# L4PER_CM_CORE register map
Vendor: Texas Instruments
Peripheral module from a debugger description file (folder TDA3x).
Registers are 32-bit, access per field, reset 0x30000 unless marked. A register's access mark holds for its fields unless they carry their own. Offsets are as the file gives them; lines under a group give offsets from that group; [hi:lo] are bit positions; {n}, {i} and the like mark numbered series; 'fields as' and 'values as' point back to an identical list; <NAME> marks a mode.

## L4PER_CM_CORE
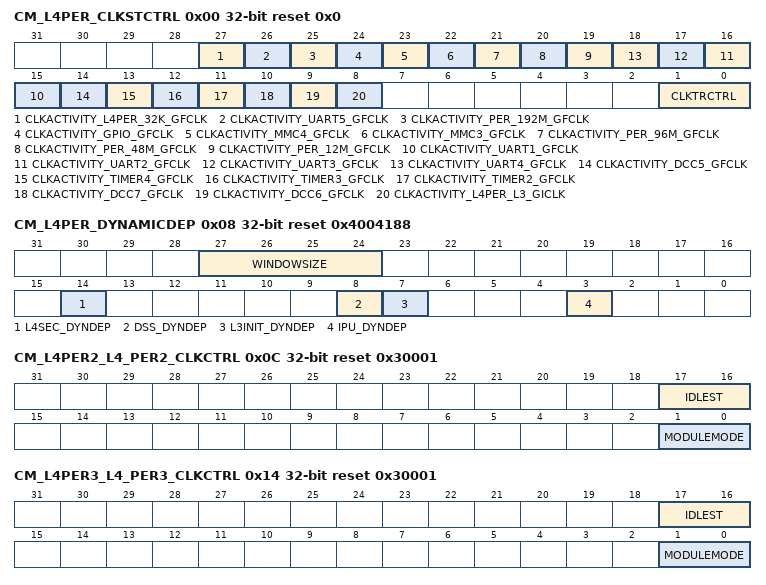
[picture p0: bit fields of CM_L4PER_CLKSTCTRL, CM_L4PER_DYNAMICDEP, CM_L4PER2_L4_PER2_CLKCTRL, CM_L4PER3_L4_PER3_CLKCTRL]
0x00 CM_L4PER_CLKSTCTRL reset 0x0 — This register enables the domain power state transition. It controls the HW supervised domain power state transition between ON-ACTIVE and ON-INACTIVE states. It also hold one status bit per clock input of the domain.
  [27] CLKACTIVITY_L4PER_32K_GFCLK ro — This field indicates the state of the L4PER_32K_FCLK clock in the domain. [warm reset insensitive]
    0=INACT (Corresponding clock is definitely gated); 1=ACT (Corresponding clock is running or gating/ungating transition is on-going)
  [26] CLKACTIVITY_UART5_GFCLK ro — This field indicates the state of the UART5_GFCLK clock in the domain. [warm reset insensitive]
    values as CLKACTIVITY_L4PER_32K_GFCLK
  [25] CLKACTIVITY_PER_192M_GFCLK ro — This field indicates the state of the PER_192M_GFCLK clock in the domain. [warm reset insensitive]
    values as CLKACTIVITY_L4PER_32K_GFCLK
  [24] CLKACTIVITY_GPIO_GFCLK ro — This field indicates the state of the GPIO_GFCLK clock in the domain. [warm reset insensitive]
    values as CLKACTIVITY_L4PER_32K_GFCLK
  [23] CLKACTIVITY_MMC4_GFCLK ro — This field indicates the state of the MMC4_GFCLK clock in the domain. [warm reset insensitive]
    values as CLKACTIVITY_L4PER_32K_GFCLK
  [22] CLKACTIVITY_MMC3_GFCLK ro — This field indicates the state of the MMC3_GFCLK clock in the domain. [warm reset insensitive]
    values as CLKACTIVITY_L4PER_32K_GFCLK
  [21] CLKACTIVITY_PER_96M_GFCLK ro — This field indicates the state of the PER_96M_GFCLK clock in the domain. [warm reset insensitive]
    values as CLKACTIVITY_L4PER_32K_GFCLK
  [20] CLKACTIVITY_PER_48M_GFCLK ro — This field indicates the state of the PER_48M_GFCLK clock in the domain. [warm reset insensitive]
    values as CLKACTIVITY_L4PER_32K_GFCLK
  [19] CLKACTIVITY_PER_12M_GFCLK ro — This field indicates the state of the PER_12M_GFCLK clock in the domain. [warm reset insensitive]
    values as CLKACTIVITY_L4PER_32K_GFCLK
  [n+14] CLKACTIVITY_UART{n}_GFCLK ro (n=1..4) — This field indicates the state of the UART{n}_GFCLK clock in the domain. [warm reset insensitive]
    values as CLKACTIVITY_L4PER_32K_GFCLK
  [14] CLKACTIVITY_DCC5_GFCLK ro — This field indicates the state of the DMT9_GFCLK clock in the domain. [warm reset insensitive]
    values as CLKACTIVITY_L4PER_32K_GFCLK
  [13] CLKACTIVITY_TIMER4_GFCLK ro — This field indicates the state of the DMT4_GFCLK clock in the domain. [warm reset insensitive]
    values as CLKACTIVITY_L4PER_32K_GFCLK
  [12] CLKACTIVITY_TIMER3_GFCLK ro — This field indicates the state of the DMT3_GFCLK clock in the domain. [warm reset insensitive]
    values as CLKACTIVITY_L4PER_32K_GFCLK
  [11] CLKACTIVITY_TIMER2_GFCLK ro — This field indicates the state of the DMT2_GFCLK clock in the domain. [warm reset insensitive]
    values as CLKACTIVITY_L4PER_32K_GFCLK
  [10] CLKACTIVITY_DCC7_GFCLK ro — This field indicates the state of the DMT11_GFCLK clock in the domain. [warm reset insensitive]
    values as CLKACTIVITY_L4PER_32K_GFCLK
  [9] CLKACTIVITY_DCC6_GFCLK ro — This field indicates the state of the DMT10_GFCLK clock in the domain. [warm reset insensitive]
    values as CLKACTIVITY_L4PER_32K_GFCLK
  [8] CLKACTIVITY_L4PER_L3_GICLK ro — This field indicates the state of the L4PER_L3_GICLK clock in the domain. [warm reset insensitive]
    values as CLKACTIVITY_L4PER_32K_GFCLK
  [1:0] CLKTRCTRL rw — Controls the clock state transition of the L4PER clock domain.
    0=NO_SLEEP (NO_SLEEP: Sleep transition cannot be initiated. Wakeup transition may however occur.); 1=SW_SLEEP (SW_SLEEP: Start a software forced sleep transition on the domain.); 2=SW_WKUP (SW_WKUP: Start a software forced wake-up transition on the domain.); 3=HW_AUTO (HW_AUTO: Automatic transition is enabled. Sleep and wakeup transition are based upon hardware conditions.)
0x08 CM_L4PER_DYNAMICDEP reset 0x4004188 — This register controls the dynamic domain depedencies from L4PER domain towards 'target' domains. It is relevant only for domain having OCP master port(s).
  [27:24] WINDOWSIZE rw — Size of sliding window used to monitor OCP interface activity for determination of auto-sleep feature. Time unit defined byCM_DYN_DEP_PRESCAL register.
  [14] L4SEC_DYNDEP ro — Dynamic dependency towards L4SEC clock domain
    1=ENABLED (Dependency is enabled)
  [8] DSS_DYNDEP ro — Dynamic dependency towards DSS clock domain
    1=ENABLED (Dependency is enabled)
  [7] L3INIT_DYNDEP ro — Dynamic dependency towards L3INIT clock domain
    1=ENABLED (Dependency is enabled)
  [3] IPU_DYNDEP ro — Dynamic dependency towards IPU clock domain
    1=ENABLED (Dependency is enabled)
0x0C CM_L4PER2_L4_PER2_CLKCTRL ro reset 0x30001 — This register manages the L4_PER2 clocks.
  [17:16] IDLEST — Module idle status. [warm reset insensitive]
    0=FUNC (Module is fully functional, including OCP); 1=TRANS (Module is performing transition: wakeup, or sleep, or sleep abortion); 2=IDLE (Module is in Idle mode (only OCP part). It is functional if using separate functional clock); 3=DISABLE (Module is disabled and cannot be accessed)
  [1:0] MODULEMODE — Control the way mandatory clocks are managed.
    1=AUTO (Module is managed automatically by HW according to clock domain transition. A clock domain sleep transition put module into idle. A wakeup domain transition put it back into function. If CLKTRCTRL=3, any OCP access to module is always granted. Module clocks may be gated according to the clock domain state.)
0x14 CM_L4PER3_L4_PER3_CLKCTRL ro reset 0x30001 — This register manages the L4_PER3 clocks.
  fields as CM_L4PER2_L4_PER2_CLKCTRL
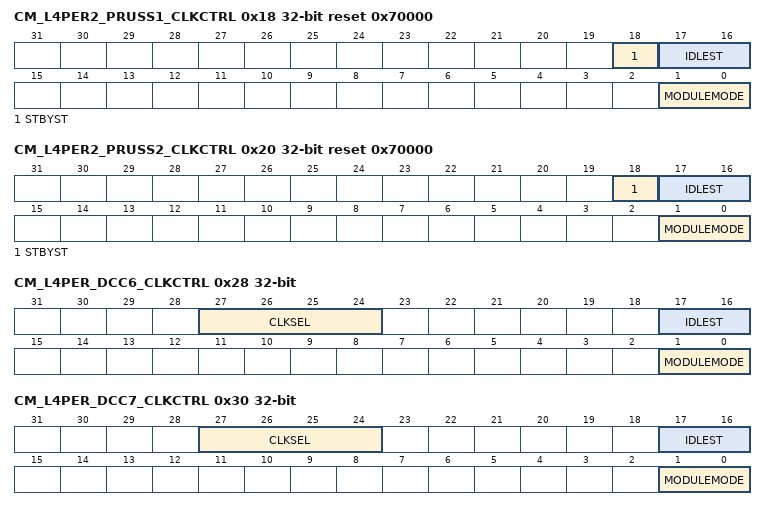
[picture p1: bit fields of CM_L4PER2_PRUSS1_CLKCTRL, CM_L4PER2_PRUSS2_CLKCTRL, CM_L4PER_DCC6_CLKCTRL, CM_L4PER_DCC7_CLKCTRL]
0x18 CM_L4PER2_PRUSS1_CLKCTRL reset 0x70000 — This register manages the PRUSS clocks.
  [18] STBYST ro — Module standby status. [warm reset insensitive]
    0=FUNC (Module is functional (not in standby)); 1=STANDBY (Module is in standby)
  [17:16] IDLEST ro — Module idle status. [warm reset insensitive]
    values as CM_L4PER2_L4_PER2_CLKCTRL.IDLEST
  [1:0] MODULEMODE rw — Control the way mandatory clocks are managed.
    0=DISABLED (Module is disabled by SW. Any OCP access to module results in an error, except if resulting from a module wakeup (asynchronous wakeup).); 2=ENABLE (Module is explicitly enabled. Interface clock (if not used for functions) may be gated according to the clock domain state. Functional clocks are guaranteed to stay present. As long as in this configuration, power domain sleep transition cannot happen.)
0x20 CM_L4PER2_PRUSS2_CLKCTRL reset 0x70000 — This register manages the PRUSS clocks.
  fields as CM_L4PER2_PRUSS1_CLKCTRL
0x28 CM_L4PER_DCC6_CLKCTRL — This register manages the DCC6 clocks.
  [27:24] CLKSEL rw — Select the source of the functional clock
    0=SEL_TIMER_SYS_CLK (Selects the TIMER_SYS_CLK as the source); 1=SEL_SYS_CLK1_32K_CLK (Selects the SYS_CLK1_32K_CLK as the source); 2=SEL_SYS_CLK2 (Selects SYS_CLK2); {v}=SEL_XREF_CLK{v-3} (Selects XREF_CLK{v-3}) (v=3..6); 7=SEL_ABE_GICLK (Selects ABE_GICLK); 8=SEL_VIDEO1_CLK (Selects VIDEO1 CLK); 9=SEL_VIDEO2_CLK (Selects VIDEO2 CLK); 10=SEL_HDMI_CLK (Selects HDMI CLK)
  [17:16] IDLEST ro — Module idle status. [warm reset insensitive]
    values as CM_L4PER2_L4_PER2_CLKCTRL.IDLEST
  [1:0] MODULEMODE rw — Control the way mandatory clocks are managed.
    values as CM_L4PER2_PRUSS1_CLKCTRL.MODULEMODE
0x30 CM_L4PER_DCC7_CLKCTRL — This register manages the DCC7 clocks.
  fields as CM_L4PER_DCC6_CLKCTRL
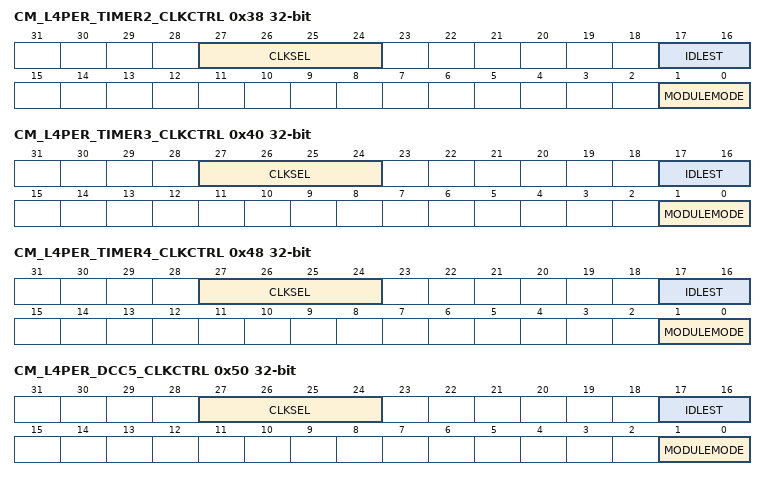
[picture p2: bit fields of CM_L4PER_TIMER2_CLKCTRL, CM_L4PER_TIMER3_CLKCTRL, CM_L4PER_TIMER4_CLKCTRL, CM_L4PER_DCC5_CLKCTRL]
0x38 CM_L4PER_TIMER2_CLKCTRL — This register manages the TIMER2 clocks.
  [27:24] CLKSEL rw — Select the source of the functional clockOthers: RESERVED .
    0=SEL_TIMER_SYS_CLK (Selects SYS_CLK1); 1=SEL_FUNC_32K_CLK (Selects FUNC_32K_CLK); 2=SEL_SYS_CLK2 (Selects SYS_CLK2); 3=SEL_XREF_CLK0 (Selects XREF_CLK0); 4=SEL_XREF_CLK1 (Selects XREF_CLK1); 5=SEL_XREF_CLK2 (Selects XREF_CLK0); 6=SEL_XREF_CLK3 (Selects XREF_CLK1); 7=SEL_ABE_GICLK (Selects ABE_GICLK); 8=SEL_VIDEO1_CLK (Selects divided version of SYS_CLK1. See); 9=SEL_VIDEO2_CLK (Selects divided version of SYS_CLK1. See); 10=SEL_HDMI_CLK (Selects divided version of SYS_CLK1. See)
  [17:16] IDLEST ro — Module idle status. [warm reset insensitive]
    values as CM_L4PER2_L4_PER2_CLKCTRL.IDLEST
  [1:0] MODULEMODE rw — Control the way mandatory clocks are managed.
    values as CM_L4PER2_PRUSS1_CLKCTRL.MODULEMODE
0x40 CM_L4PER_TIMER3_CLKCTRL — This register manages the TIMER3 clocks.
  [27:24] CLKSEL rw — Select the source of the functional clockOthers: RESERVED enum=RESERVED4 .
    0=SEL_TIMER_SYS_CLK (Selects SYS_CLK1); 1=SEL_FUNC_32K_CLK (Selects FUNC_32K_CLK); 2=SEL_SYS_CLK2 (Selects SYS_CLK2); 3=SEL_XREF_CLK0 (Selects XREF_CLK0); 4=SEL_XREF_CLK1 (Selects XREF_CLK1); 5=SEL_XREF_CLK2 (Selects XREF_CLK0); 6=SEL_XREF_CLK3 (Selects XREF_CLK1); 7=SEL_PER_ABE_X1_GFCLK (Selects ABE_GICLK); 8=SEL_VIDEO1_CLK (Selects divided version of SYS_CLK1. See); 9=SEL_VIDEO2_CLK (Selects divided version of SYS_CLK1. See); 10=SEL_HDMI_CLK (Selects divided version of SYS_CLK1. See)
  [17:16] IDLEST ro — Module idle status. [warm reset insensitive]
    values as CM_L4PER2_L4_PER2_CLKCTRL.IDLEST
  [1:0] MODULEMODE rw — Control the way mandatory clocks are managed.
    values as CM_L4PER2_PRUSS1_CLKCTRL.MODULEMODE
0x48 CM_L4PER_TIMER4_CLKCTRL — This register manages the TIMER4 clocks.
  [27:24] CLKSEL rw — Select the source of the functional clockOthers: RESERVED .
    values as CM_L4PER_TIMER3_CLKCTRL.CLKSEL
  [17:16] IDLEST ro — Module idle status. [warm reset insensitive]
    values as CM_L4PER2_L4_PER2_CLKCTRL.IDLEST
  [1:0] MODULEMODE rw — Control the way mandatory clocks are managed.
    values as CM_L4PER2_PRUSS1_CLKCTRL.MODULEMODE
0x50 CM_L4PER_DCC5_CLKCTRL — This register manages the DCC5 clocks.
  [27:24] CLKSEL rw — Select the source of the functional clock
    0=SEL_TIMER_SYS_CLK (Selects the TIMER_SYS_CLK as the source); 1=SEL_SYS_CLK1_32K_CLK (Selects the SYS_CLK1_32K_CLK as the source); 2=SEL_SYS_CLK2 (Selects SYS_CLK2); {v}=SEL_XREF_CLK{v-3} (Selects XREF_CLK{v-3}) (v=3..6); 7=SEL_PER_ABE_X1_GFCLK (Selects PER_ABE_X1 CLK); 8=SEL_VIDEO1_CLK (Selects VIDEO1 CLK); 9=SEL_VIDEO2_CLK (Selects VIDEO2 CLK); 10=SEL_HDMI_CLK (Selects HDMI CLK)
  [17:16] IDLEST ro — Module idle status. [warm reset insensitive]
    values as CM_L4PER2_L4_PER2_CLKCTRL.IDLEST
  [1:0] MODULEMODE rw — Control the way mandatory clocks are managed.
    values as CM_L4PER2_PRUSS1_CLKCTRL.MODULEMODE
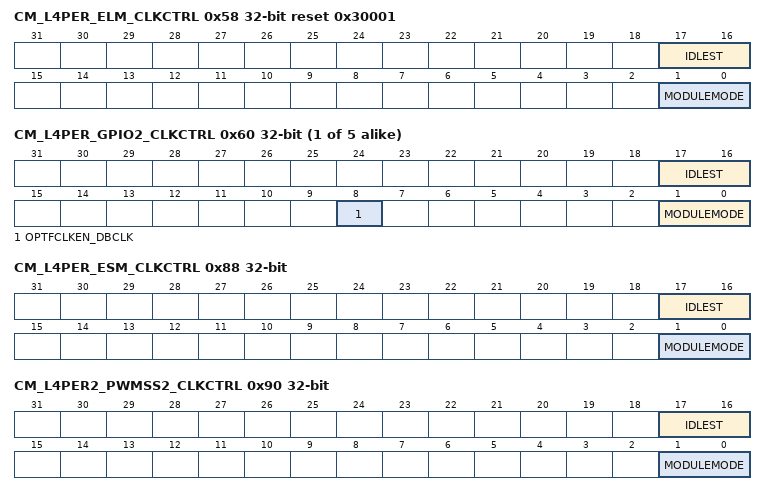
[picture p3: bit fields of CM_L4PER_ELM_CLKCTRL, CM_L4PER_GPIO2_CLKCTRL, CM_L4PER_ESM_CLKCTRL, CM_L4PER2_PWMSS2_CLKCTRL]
0x58 CM_L4PER_ELM_CLKCTRL ro reset 0x30001 — This register manages the ELM clocks.
  fields as CM_L4PER2_L4_PER2_CLKCTRL
{0x50+8i} CM_L4PER_GPIO{i}_CLKCTRL (i=2..6) — This register manages the GPIO{i} clocks.
  [17:16] IDLEST ro — Module idle status. [warm reset insensitive]
    values as CM_L4PER2_L4_PER2_CLKCTRL.IDLEST
  [8] OPTFCLKEN_DBCLK rw — Optional functional clock control.
    0=FCLK_DIS (Optional functional clock is disabled); 1=FCLK_EN (Optional functional clock is enabled)
  [1:0] MODULEMODE rw — Control the way mandatory clocks are managed.
    0=DISABLED (Module is disabled by SW. Any OCP access to module results in an error, except if resulting from a module wakeup (asynchronous wakeup).); 1=AUTO (Module is managed automatically by HW according to clock domain transition. A clock domain sleep transition put module into idle. A wakeup domain transition put it back into function. If CLKTRCTRL=3, any OCP access to module is always granted. Module clocks may be gated according to the clock domain state.)
0x88 CM_L4PER_ESM_CLKCTRL — This register manages the ESM clocks.
  [17:16] IDLEST ro — Module idle status. [warm reset insensitive]
    values as CM_L4PER2_L4_PER2_CLKCTRL.IDLEST
  [1:0] MODULEMODE rw — Control the way mandatory clocks are managed.
    values as CM_L4PER2_PRUSS1_CLKCTRL.MODULEMODE
0x90 CM_L4PER2_PWMSS2_CLKCTRL — This register manages the PWMSS1 clocks.
  fields as CM_L4PER_ESM_CLKCTRL
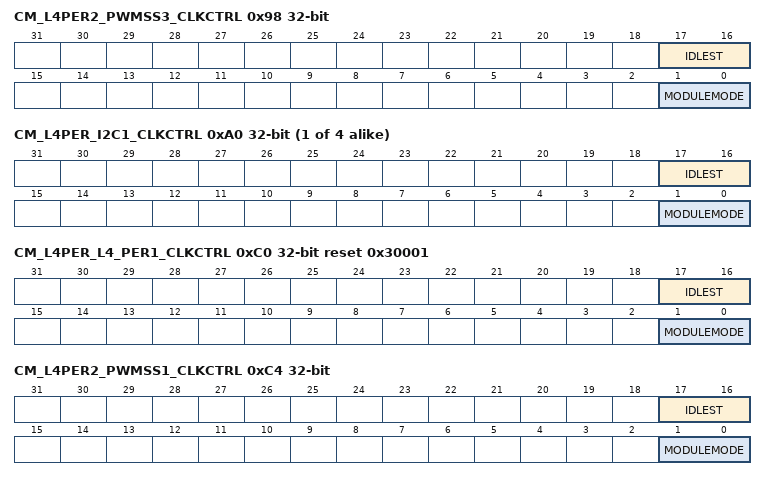
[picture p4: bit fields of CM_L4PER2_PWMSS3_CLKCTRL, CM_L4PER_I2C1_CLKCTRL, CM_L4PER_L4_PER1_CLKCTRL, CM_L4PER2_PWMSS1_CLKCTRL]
0x98 CM_L4PER2_PWMSS3_CLKCTRL — This register manages the PWMSS2 clocks.
  fields as CM_L4PER_ESM_CLKCTRL
{0x98+8i} CM_L4PER_I2C{i}_CLKCTRL (i=1..4) — This register manages the I2C{i} clocks.
  fields as CM_L4PER_ESM_CLKCTRL
0xC0 CM_L4PER_L4_PER1_CLKCTRL ro reset 0x30001 — This register manages the L4_PER1 clocks.
  fields as CM_L4PER2_L4_PER2_CLKCTRL
0xC4 CM_L4PER2_PWMSS1_CLKCTRL — This register manages the PWMSS1 clocks.
  fields as CM_L4PER_ESM_CLKCTRL
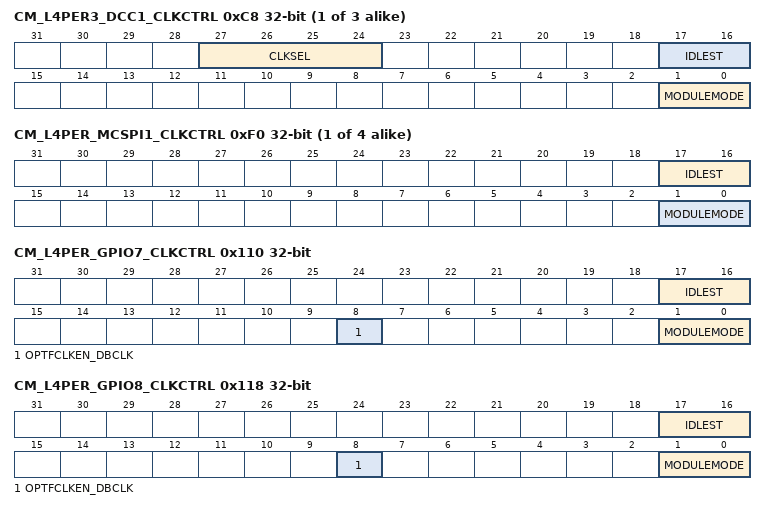
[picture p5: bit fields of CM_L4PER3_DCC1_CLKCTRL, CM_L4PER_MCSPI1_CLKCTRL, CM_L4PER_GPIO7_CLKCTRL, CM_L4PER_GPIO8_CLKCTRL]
{0xC0+8i} CM_L4PER3_DCC{i}_CLKCTRL (i=1..3) — This register manages the DCC{i} clocks.
  fields as CM_L4PER_DCC5_CLKCTRL
{0xE8+8i} CM_L4PER_MCSPI{i}_CLKCTRL (i=1..4) — This register manages the MCSPI{i} clocks.
  fields as CM_L4PER_ESM_CLKCTRL
0x110 CM_L4PER_GPIO7_CLKCTRL — This register manages the GPIO7 clocks.
  fields as CM_L4PER_GPIO2_CLKCTRL
0x118 CM_L4PER_GPIO8_CLKCTRL — This register manages the GPIO8 clocks.
  fields as CM_L4PER_GPIO2_CLKCTRL
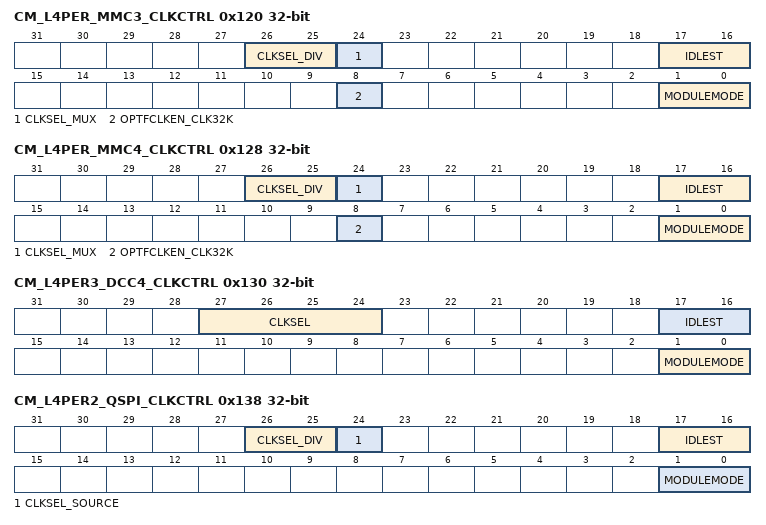
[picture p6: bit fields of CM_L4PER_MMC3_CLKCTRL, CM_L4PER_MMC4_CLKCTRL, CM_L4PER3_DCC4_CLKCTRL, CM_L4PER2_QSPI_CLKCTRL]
0x120 CM_L4PER_MMC3_CLKCTRL — This register manages the MMC3 clocks.
  [26:25] CLKSEL_DIV rw — Selects the divider value
    0=MMCCLK_DIV_1 (Select MMC CLK divided by 1); 1=MMCCLK_DIV_2 (Select MMC CLK divided by 2); 2=MMCCLK_DIV_4 (Selects MMC CLK divided by 4)
  [24] CLKSEL_MUX rw — Select the clock for the MMC from DPLL_PER.
    0=SEL_FUNC_48M_CLK (Selects FUNC_48M_CLK); 1=SEL_FUNC_192M_CLK (Selects FUNC_192M_CLK)
  [17:16] IDLEST ro — Module idle status. [warm reset insensitive]
    values as CM_L4PER2_L4_PER2_CLKCTRL.IDLEST
  [8] OPTFCLKEN_CLK32K rw — MMC optional clock control: 32K CLK
    values as CM_L4PER_GPIO2_CLKCTRL.OPTFCLKEN_DBCLK
  [1:0] MODULEMODE rw — Control the way mandatory clocks are managed.
    values as CM_L4PER2_PRUSS1_CLKCTRL.MODULEMODE
0x128 CM_L4PER_MMC4_CLKCTRL — This register manages the MMC4 clocks.
  [26:25] CLKSEL_DIV rw — Selects the divider value
    0=MMCCLK_DIV_1 (Selects MMC CLK divided by 1); 1=MMCCLK_DIV_2 (Selects MMC CLK divided by 2); 2=MMCCLK_DIV_4 (Selects MMC CLK divided by 4)
  [24] CLKSEL_MUX rw — Select the clock for the MMC from DPLL_PER.
    values as CM_L4PER_MMC3_CLKCTRL.CLKSEL_MUX
  [17:16] IDLEST ro — Module idle status. [warm reset insensitive]
    values as CM_L4PER2_L4_PER2_CLKCTRL.IDLEST
  [8] OPTFCLKEN_CLK32K rw — MMC optional clock control: 32K CLK
    values as CM_L4PER_GPIO2_CLKCTRL.OPTFCLKEN_DBCLK
  [1:0] MODULEMODE rw — Control the way mandatory clocks are managed.
    values as CM_L4PER2_PRUSS1_CLKCTRL.MODULEMODE
0x130 CM_L4PER3_DCC4_CLKCTRL — This register manages the DCC4 clocks.
  fields as CM_L4PER_DCC5_CLKCTRL
0x138 CM_L4PER2_QSPI_CLKCTRL — This register manages the QSPI clocks.
  [26:25] CLKSEL_DIV rw — QSPI clock divide ratio.
    0=DIV1 (QSPI clock is divided by 1.); 1=DIV2 (QSPI clock is divided by 2.); 2=DIV4 (QSPI clock is divided by 4.)
  [24] CLKSEL_SOURCE rw — Selects the source of the functional clock.
    0=SEL_FUNC_128M_CLK (FUNC_128M_CLK from DPLL_PER is selected); 1=SEL_PER_QSPI_CLK (Selects PER_QSPI_CLK from DPLL_PER)
  [17:16] IDLEST ro — Module idle status. [warm reset insensitive]
    values as CM_L4PER2_L4_PER2_CLKCTRL.IDLEST
  [1:0] MODULEMODE rw — Control the way mandatory clocks are managed.
    0=DISABLED (Module is disabled by SW. Any OCP access to module results in an error, except if resulting from a module wakeup (asynchronous wakeup).); 2=ENABLED (Module is explicitly enabled. Interface clock (if not used for functions) may be gated according to the clock domain state. Functional clocks are guaranteed to stay present. As long as in this configuration, power domain sleep transition cannot happen.)
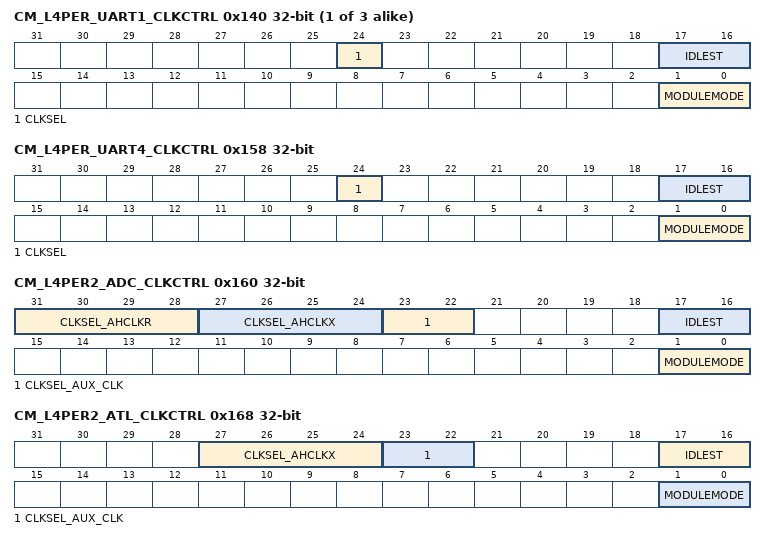
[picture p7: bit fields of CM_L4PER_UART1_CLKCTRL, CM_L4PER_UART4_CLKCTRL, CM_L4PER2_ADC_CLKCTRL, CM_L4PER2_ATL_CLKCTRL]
{0x138+8i} CM_L4PER_UART{i}_CLKCTRL (i=1..3) — This register manages the UART{i} clocks.
  [24] CLKSEL rw — Selects functional clock for UART between FUNC_48M_CLK and FUNC_192M_CLK
    values as CM_L4PER_MMC3_CLKCTRL.CLKSEL_MUX
  [17:16] IDLEST ro — Module idle status. [warm reset insensitive]
    values as CM_L4PER2_L4_PER2_CLKCTRL.IDLEST
  [1:0] MODULEMODE rw — Control the way mandatory clocks are managed.
    values as CM_L4PER2_PRUSS1_CLKCTRL.MODULEMODE
0x158 CM_L4PER_UART4_CLKCTRL — This register manages the UART4 clocks.
  [24] CLKSEL rw — Selects functional clock for UART between FUNCTION_48M_CLK and FUNC_192M_CLK
    values as CM_L4PER_MMC3_CLKCTRL.CLKSEL_MUX
  [17:16] IDLEST ro — Module idle status. [warm reset insensitive]
    values as CM_L4PER2_L4_PER2_CLKCTRL.IDLEST
  [1:0] MODULEMODE rw — Control the way mandatory clocks are managed.
    values as CM_L4PER2_PRUSS1_CLKCTRL.MODULEMODE
0x160 CM_L4PER2_ADC_CLKCTRL — This register manages the ADC clocks. In TDA2x, this register is CM_L4PER2_MCASP2_CLKCTRL
  [31:28] CLKSEL_AHCLKR rw — Selects reference clock for AHCLKR
    0=SEL_ABE_24M_GFCLK (Selects ABE_24M_GFCLK); 1=SEL_ABE_SYS_CLK (Selects ABE_SYS_CLK); 2=SEL_FUNC_24M_GFCLK (Selects FUNC_24M_GFCLK); 3=SEL_CRC_CLK3 (Selects ATL CLK3); 4=SEL_CRC_CLK2 (Selects ATL CLK2); 5=SEL_CRC_CLK1 (Selects ATL CLK1); 6=SEL_CRC_CLK0 (Selects ATL CLK0); 7=SEL_SYS_SLK2 (Selects SYS_CLK2); {v}=SEL_XREF_CLK{v-8} (Selects XREF_CLK{v-8}) (v=8..11); 12=SEL_MLB_CLK (Selects MLB_CLK); 13=SEL_MLBP_CLK (Selects MLBP_CLK)
  [27:24] CLKSEL_AHCLKX rw — Selects reference clock for AHCLKX
    values as CLKSEL_AHCLKR
  [23:22] CLKSEL_AUX_CLK rw — Selects the source of the AUX clock
    0=SEL_PER_ABE_X1_GFCLK (Selects PER_ABE_X1_GFCLK); 1=SEL_VIDEO1_CLK (Selects VIDEO1 CLK); 2=SEL_VIDEO2_CLK (Selects VIDEO2 CLK); 3=SEL_HDMI_CLK (Selects HDMI CLK)
  [17:16] IDLEST ro — Module idle status. [warm reset insensitive]
    values as CM_L4PER2_L4_PER2_CLKCTRL.IDLEST
  [1:0] MODULEMODE rw — Control the way mandatory clocks are managed.
    values as CM_L4PER2_PRUSS1_CLKCTRL.MODULEMODE
0x168 CM_L4PER2_ATL_CLKCTRL — This register manages the ATL module mode (SR2.0). In TDA2x, this register is CM_L4PER2_MCASP3_CLKCTRL
  [27:24] CLKSEL_AHCLKX rw — Selects reference clock for AHCLKX
    values as CM_L4PER2_ADC_CLKCTRL.CLKSEL_AHCLKR
  [23:22] CLKSEL_AUX_CLK rw — Selects the source of the AUX clock
    values as CM_L4PER2_ADC_CLKCTRL.CLKSEL_AUX_CLK
  [17:16] IDLEST ro — Module idle status. [warm reset insensitive]
    values as CM_L4PER2_L4_PER2_CLKCTRL.IDLEST
  [1:0] MODULEMODE rw — Control the way mandatory clocks are managed.
    values as CM_L4PER2_PRUSS1_CLKCTRL.MODULEMODE
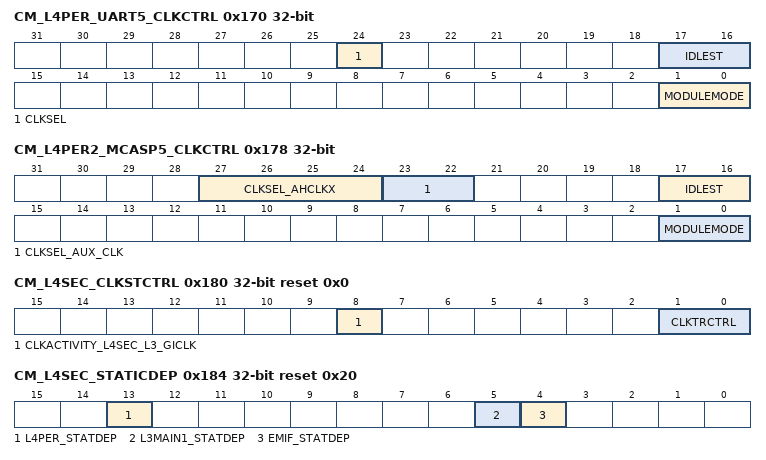
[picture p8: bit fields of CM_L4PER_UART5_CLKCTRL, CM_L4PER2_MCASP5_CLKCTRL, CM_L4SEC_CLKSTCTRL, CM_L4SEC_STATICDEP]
0x170 CM_L4PER_UART5_CLKCTRL — This register manages the UART5 clocks.
  fields as CM_L4PER_UART4_CLKCTRL
0x178 CM_L4PER2_MCASP5_CLKCTRL — This register manages the MCASP3 clocks (SR2.0).
  [27:24] CLKSEL_AHCLKX rw — Selects reference clock for AHCLKX
    0=SEL_ABE_24M_GFCLK (Selects ABE_24M_GFCLK); 1=SEL_ABE_SYS_CLK (Selects ABE_SYS_CLK); 2=SEL_FUNC_24M_GFCLK (Selects FUNC_24M_GFCLK); 3=SEL_ATL_CLK3 (Selects ATL_CLK3); 4=SEL_ATL_CLK2 (Selects ATL_CLK2); 5=SEL_ATL_CLK1 (Selects ATL_CLK1); 6=SEL_ATL_CLK0 (Selects ATL_CLK0); 7=SEL_SYS_SLK2 (Selects SYS_CLK2); 8=SEL_XREF_CLK0 (Selects XREF_CLK0); 9=SEL_XREF_CLK1 (Selects XREF_CLK1); 10=SEL_XREF_CLK2 (Selects XREF_CLK2); 11=SEL_XREF_CLK3 (Selects XREF_CLK1); 12=SEL_MLB_CLK (Selects divided version of SYS_CLK1. See); 13=SEL_MLBP_CLK (Selects divided version of SYS_CLK1. See)
  [23:22] CLKSEL_AUX_CLK rw — Selects the source of the AUX clock.
    0=SEL_PER_ABE_X1_GFCLK (Selects divided version of L4_ICLK. See); 1=SEL_VIDEO1_CLK (Selects divided version of SYS_CLK1. See); 2=SEL_VIDEO2_CLK (Selects divided version of SYS_CLK1. See); 3=SEL_HDMI_CLK (Selects divided version of SYS_CLK1. See)
  [17:16] IDLEST ro — Module idle status. [warm reset insensitive]
    values as CM_L4PER2_L4_PER2_CLKCTRL.IDLEST
  [1:0] MODULEMODE rw — Control the way mandatory clocks are managed.
    values as CM_L4PER2_PRUSS1_CLKCTRL.MODULEMODE
0x180 CM_L4SEC_CLKSTCTRL reset 0x0 — This register enables the domain power state transition. It controls the HW supervised domain power state transition between ON-ACTIVE and ON-INACTIVE states. It also hold one status bit per clock input of the domain.
  [8] CLKACTIVITY_L4SEC_L3_GICLK ro — This field indicates the state of the L3_SECURE_GICLK clock in the domain. [warm reset insensitive]
    values as CM_L4PER_CLKSTCTRL.CLKACTIVITY_L4PER_32K_GFCLK
  [1:0] CLKTRCTRL rw — Controls the clock state transition of the L4PER clock domain.
    values as CM_L4PER_CLKSTCTRL.CLKTRCTRL
0x184 CM_L4SEC_STATICDEP reset 0x20 — This register controls the static domain depedencies from L4SEC domain towards 'target' domains. It is relevant only for domain having system initiator(s).
  [13] L4PER_STATDEP rw — Static dependency towards L4PER1 clock domain
    0=DISABLED (Dependency is disabled); 1=ENABLED (Dependency is enabled)
  [5] L3MAIN1_STATDEP ro — Static dependency towards L3MAIN1 clock domain
    1=ENABLED (Dependency is enabled)
  [4] EMIF_STATDEP rw — Static dependency towards EMIF clock domain
    values as L4PER_STATDEP
0x188 CM_L4SEC_DYNAMICDEP ro reset 0x0 — This register controls the dynamic domain depedencies from L4SEC domain towards 'target' domains. It is relevant only for domain having OCP master port(s).
  [5] L3MAIN1_DYNDEP — Dynamic dependency towards L3MAIN1 clock domain
    0=DISABLED (Dependency is disabled)
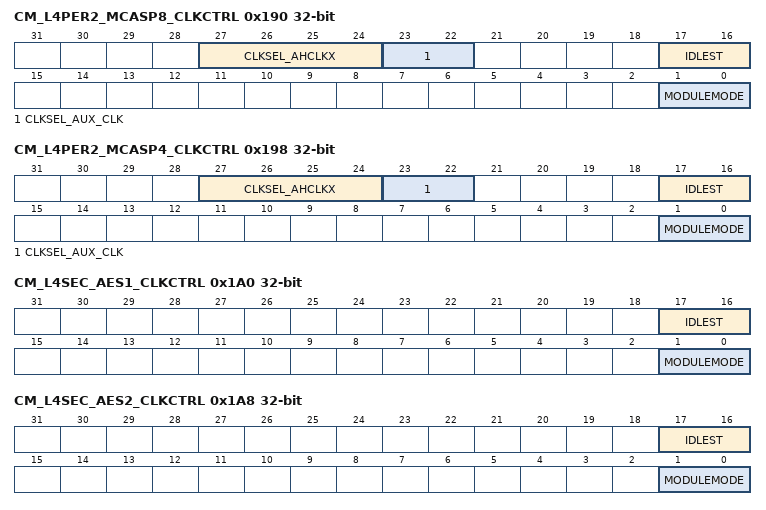
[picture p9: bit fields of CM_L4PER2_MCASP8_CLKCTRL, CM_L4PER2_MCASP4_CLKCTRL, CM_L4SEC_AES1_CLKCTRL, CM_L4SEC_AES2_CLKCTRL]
0x190 CM_L4PER2_MCASP8_CLKCTRL — This register manages the MCASP8 clocks.
  [27:24] CLKSEL_AHCLKX rw — Selects reference clock for AHCLKX
    0=SEL_ABE_24M_GFCLK (Selects ABE_24M_GFCLK); 1=SEL_ABE_SYS_CLK (Selects ABE_SYS_CLK); 2=SEL_FUNC_24M_GFCLK (Selects FUNC_24M_GFCLK); 3=SEL_CRC_CLK3 (Selects CRC CLK3); 4=SEL_CRC_CLK2 (Selects CRC CLK2); 5=SEL_CRC_CLK1 (Selects CRC CLK1); 6=SEL_CRC_CLK0 (Selects CRC CLK0); 7=SEL_SYS_SLK2 (Selects SYS_CLK2); {v}=SEL_XREF_CLK{v-8} (Selects XREF_CLK{v-8}) (v=8..11); 12=SEL_MLB_CLK (Selects MLB_CLK); 13=SEL_MLBP_CLK (Selects MLBP_CLK)
  [23:22] CLKSEL_AUX_CLK rw — Selects the source of the AUX clock
    values as CM_L4PER2_ADC_CLKCTRL.CLKSEL_AUX_CLK
  [17:16] IDLEST ro — Module idle status. [warm reset insensitive]
    values as CM_L4PER2_L4_PER2_CLKCTRL.IDLEST
  [1:0] MODULEMODE rw — Control the way mandatory clocks are managed.
    values as CM_L4PER2_PRUSS1_CLKCTRL.MODULEMODE
0x198 CM_L4PER2_MCASP4_CLKCTRL — This register manages the MCASP2 clocks (SR2.0).
  fields as CM_L4PER2_MCASP5_CLKCTRL
0x1A0 CM_L4SEC_AES1_CLKCTRL — This register manages the AES1 clocks.
  [17:16] IDLEST ro — Module idle status. [warm reset insensitive]
    values as CM_L4PER2_L4_PER2_CLKCTRL.IDLEST
  [1:0] MODULEMODE rw — Control the way mandatory clocks are managed.
    values as CM_L4PER_GPIO2_CLKCTRL.MODULEMODE
0x1A8 CM_L4SEC_AES2_CLKCTRL — This register manages the AES2 clocks.
  fields as CM_L4SEC_AES1_CLKCTRL
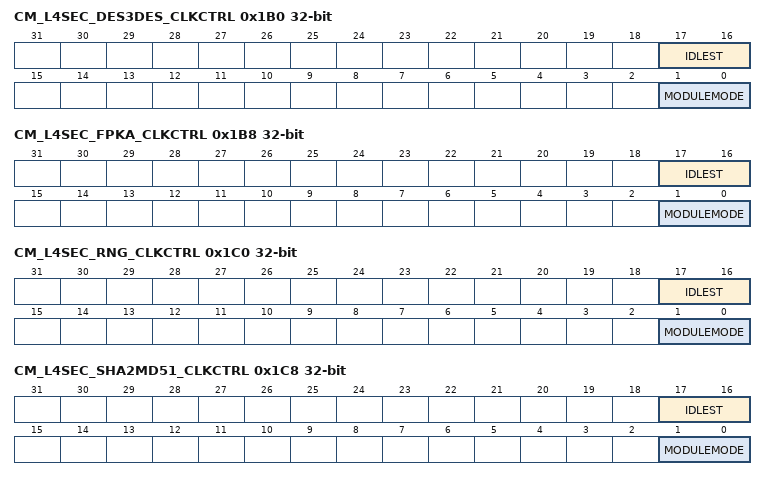
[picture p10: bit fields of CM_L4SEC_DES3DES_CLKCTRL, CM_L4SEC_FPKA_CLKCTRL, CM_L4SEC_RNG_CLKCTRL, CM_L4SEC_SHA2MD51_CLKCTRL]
0x1B0 CM_L4SEC_DES3DES_CLKCTRL — This register manages the DES3DES clocks.
  fields as CM_L4SEC_AES1_CLKCTRL
0x1B8 CM_L4SEC_FPKA_CLKCTRL — This register manages the FPKA clocks.
  fields as CM_L4PER_ESM_CLKCTRL
0x1C0 CM_L4SEC_RNG_CLKCTRL — This register manages the RNG clocks.
  fields as CM_L4SEC_AES1_CLKCTRL
0x1C8 CM_L4SEC_SHA2MD51_CLKCTRL — This register manages the SHA2MD51 clocks.
  fields as CM_L4SEC_AES1_CLKCTRL
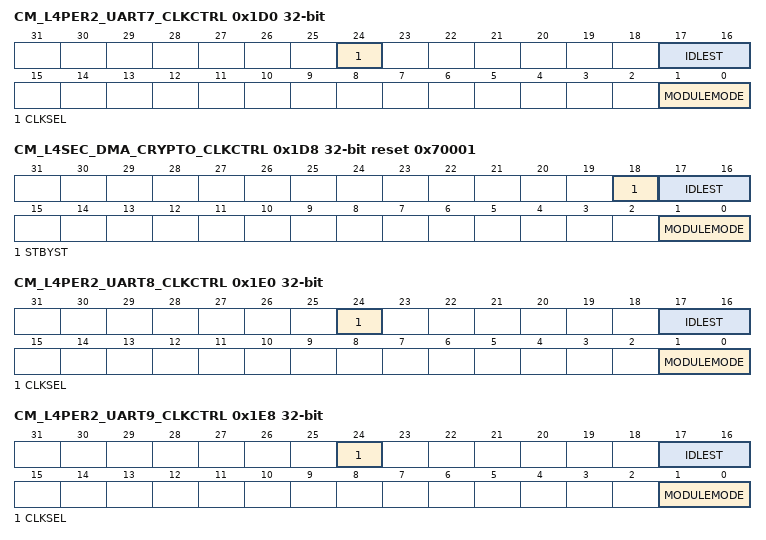
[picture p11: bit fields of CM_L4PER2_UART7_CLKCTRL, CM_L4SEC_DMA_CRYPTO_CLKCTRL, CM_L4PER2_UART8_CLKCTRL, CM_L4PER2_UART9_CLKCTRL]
0x1D0 CM_L4PER2_UART7_CLKCTRL — This register manages the UART7 clocks.
  fields as CM_L4PER_UART4_CLKCTRL
0x1D8 CM_L4SEC_DMA_CRYPTO_CLKCTRL ro reset 0x70001 — This register manages the DMA_CRYPTO clocks.
  [18] STBYST — Module standby status. [warm reset insensitive]
    values as CM_L4PER2_PRUSS1_CLKCTRL.STBYST
  [17:16] IDLEST — Module idle status. [warm reset insensitive]
    values as CM_L4PER2_L4_PER2_CLKCTRL.IDLEST
  [1:0] MODULEMODE — Control the way mandatory clocks are managed.
    values as CM_L4PER2_L4_PER2_CLKCTRL.MODULEMODE
0x1E0 CM_L4PER2_UART8_CLKCTRL — This register manages the UART8 clocks.
  fields as CM_L4PER_UART4_CLKCTRL
0x1E8 CM_L4PER2_UART9_CLKCTRL — This register manages the UART9 clocks.
  fields as CM_L4PER_UART4_CLKCTRL
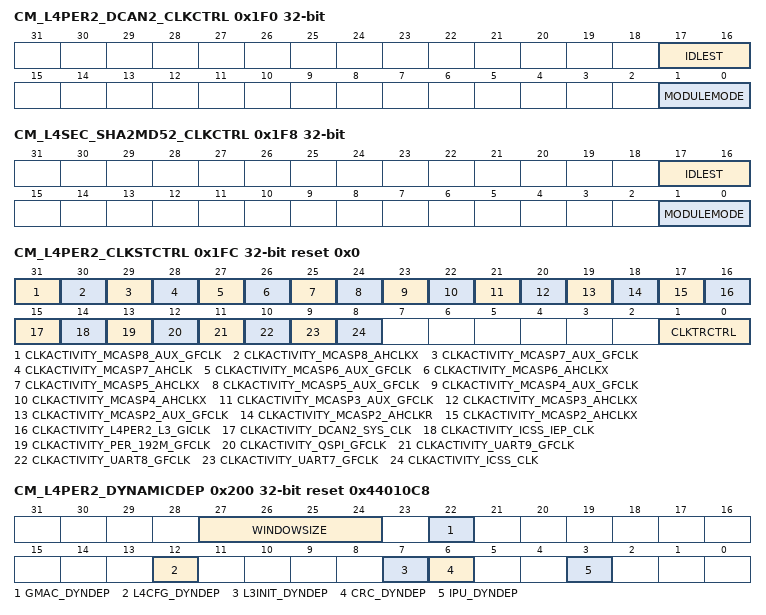
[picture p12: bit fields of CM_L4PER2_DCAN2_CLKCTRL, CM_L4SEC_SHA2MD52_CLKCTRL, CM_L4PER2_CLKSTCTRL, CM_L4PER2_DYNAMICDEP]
0x1F0 CM_L4PER2_DCAN2_CLKCTRL — This register manages the MCAN clocks (SR2.0) or DCAN2 clocks (SR1.0).
  fields as CM_L4PER_ESM_CLKCTRL
0x1F8 CM_L4SEC_SHA2MD52_CLKCTRL — This register manages the SHA2MD52 clocks.
  fields as CM_L4SEC_AES1_CLKCTRL
0x1FC CM_L4PER2_CLKSTCTRL reset 0x0 — This register enables the domain power state transition. It controls the HW supervised domain power state transition between ON-ACTIVE and ON-INACTIVE states. It also hold one status bit per clock input of the domain.
  [31] CLKACTIVITY_MCASP8_AUX_GFCLK ro — This field indicates the state of the MCASP8_AUX_GFCLK clock in the domain. [warm reset insensitive]
    values as CM_L4PER_CLKSTCTRL.CLKACTIVITY_L4PER_32K_GFCLK
  [30] CLKACTIVITY_MCASP8_AHCLKX ro — This field indicates the state of the MCASP8_AHCLKX clock in the domain. [warm reset insensitive]
    values as CM_L4PER_CLKSTCTRL.CLKACTIVITY_L4PER_32K_GFCLK
  [29] CLKACTIVITY_MCASP7_AUX_GFCLK ro — This field indicates the state of the MCASP7_AUX_GFCLK clock in the domain. [warm reset insensitive]
    values as CM_L4PER_CLKSTCTRL.CLKACTIVITY_L4PER_32K_GFCLK
  [28] CLKACTIVITY_MCASP7_AHCLK ro — This field indicates the state of the MCASP7_AHCLKX clock in the domain. [warm reset insensitive]
    values as CM_L4PER_CLKSTCTRL.CLKACTIVITY_L4PER_32K_GFCLK
  [27] CLKACTIVITY_MCASP6_AUX_GFCLK ro — This field indicates the state of the MCASP6_AUX_GFCLK clock in the domain. [warm reset insensitive]
    values as CM_L4PER_CLKSTCTRL.CLKACTIVITY_L4PER_32K_GFCLK
  [26] CLKACTIVITY_MCASP6_AHCLKX ro — This field indicates the state of the MCASP6_AUX_GFCLK clock in the domain. [warm reset insensitive]
    values as CM_L4PER_CLKSTCTRL.CLKACTIVITY_L4PER_32K_GFCLK
  [25] CLKACTIVITY_MCASP5_AHCLKX ro — This field indicates the state of the MCASP5_AHCLKX clock in the domain. [warm reset insensitive]
    values as CM_L4PER_CLKSTCTRL.CLKACTIVITY_L4PER_32K_GFCLK
  [24] CLKACTIVITY_MCASP5_AUX_GFCLK ro — This field indicates the state of the MCASP5_AUX_GFCLK clock in the domain. [warm reset insensitive]
    values as CM_L4PER_CLKSTCTRL.CLKACTIVITY_L4PER_32K_GFCLK
  [23] CLKACTIVITY_MCASP4_AUX_GFCLK ro — This field indicates the state of the MCASP4_AUX_GFCLK clock in the domain. [warm reset insensitive]
    values as CM_L4PER_CLKSTCTRL.CLKACTIVITY_L4PER_32K_GFCLK
  [22] CLKACTIVITY_MCASP4_AHCLKX ro — This field indicates the state of the MCASP4_AHCLKX clock in the domain. [warm reset insensitive]
    values as CM_L4PER_CLKSTCTRL.CLKACTIVITY_L4PER_32K_GFCLK
  [21] CLKACTIVITY_MCASP3_AUX_GFCLK ro — This field indicates the state of the MCASP3_AUX_GFCLK clock in the domain. [warm reset insensitive]
    values as CM_L4PER_CLKSTCTRL.CLKACTIVITY_L4PER_32K_GFCLK
  [20] CLKACTIVITY_MCASP3_AHCLKX ro — This field indicates the state of the MCASP3_AHCLKX clock in the domain. [warm reset insensitive]
    values as CM_L4PER_CLKSTCTRL.CLKACTIVITY_L4PER_32K_GFCLK
  [19] CLKACTIVITY_MCASP2_AUX_GFCLK ro — This field indicates the state of the ADC_AUX_GFCLK clock in the domain. [warm reset insensitive]
    values as CM_L4PER_CLKSTCTRL.CLKACTIVITY_L4PER_32K_GFCLK
  [18] CLKACTIVITY_MCASP2_AHCLKR ro — This field indicates the state of the ADC_AHCLKR clock in the domain. [warm reset insensitive]
    values as CM_L4PER_CLKSTCTRL.CLKACTIVITY_L4PER_32K_GFCLK
  [17] CLKACTIVITY_MCASP2_AHCLKX ro — This field indicates the state of the ADC_AHCLKX clock in the domain. [warm reset insensitive]
    values as CM_L4PER_CLKSTCTRL.CLKACTIVITY_L4PER_32K_GFCLK
  [16] CLKACTIVITY_L4PER2_L3_GICLK ro — This field indicates the state of the L4PER2_L3_GICLK clock in the domain. [warm reset insensitive]
    values as CM_L4PER_CLKSTCTRL.CLKACTIVITY_L4PER_32K_GFCLK
  [15] CLKACTIVITY_DCAN2_SYS_CLK ro — This field indicates the state of the MCAN_CLK clock in the domain. [warm reset insensitive]
    values as CM_L4PER_CLKSTCTRL.CLKACTIVITY_L4PER_32K_GFCLK
  [14] CLKACTIVITY_ICSS_IEP_CLK ro — This field indicates the state of the ICSS_IEP_CLK clock in the domain. [warm reset insensitive]
    values as CM_L4PER_CLKSTCTRL.CLKACTIVITY_L4PER_32K_GFCLK
  [13] CLKACTIVITY_PER_192M_GFCLK ro — This field indicates the state of the PER_192M_GFCLK clock in the domain. [warm reset insensitive]
    values as CM_L4PER_CLKSTCTRL.CLKACTIVITY_L4PER_32K_GFCLK
  [12] CLKACTIVITY_QSPI_GFCLK ro — This field indicates the state of the QSPI_GFCLK clock in the domain. [warm reset insensitive]
    values as CM_L4PER_CLKSTCTRL.CLKACTIVITY_L4PER_32K_GFCLK
  [11] CLKACTIVITY_UART9_GFCLK ro — This field indicates the state of the UART9_GFCLK clock in the domain. [warm reset insensitive]
    values as CM_L4PER_CLKSTCTRL.CLKACTIVITY_L4PER_32K_GFCLK
  [10] CLKACTIVITY_UART8_GFCLK ro — This field indicates the state of the UART8_GFCLK clock in the domain. [warm reset insensitive]
    values as CM_L4PER_CLKSTCTRL.CLKACTIVITY_L4PER_32K_GFCLK
  [9] CLKACTIVITY_UART7_GFCLK ro — This field indicates the state of the UART7_GFCLK clock in the domain. [warm reset insensitive]
    values as CM_L4PER_CLKSTCTRL.CLKACTIVITY_L4PER_32K_GFCLK
  [8] CLKACTIVITY_ICSS_CLK ro — This field indicates the state of the ICSS_CLK clock in the domain. [warm reset insensitive]
    values as CM_L4PER_CLKSTCTRL.CLKACTIVITY_L4PER_32K_GFCLK
  [1:0] CLKTRCTRL rw — Controls the clock state transition of the L4PER clock domain.
    values as CM_L4PER_CLKSTCTRL.CLKTRCTRL
0x200 CM_L4PER2_DYNAMICDEP reset 0x44010C8 — This register controls the dynamic domain depedencies from L4PER2 domain towards 'target' domains. It is relevant only for domain having OCP master port(s).
  [27:24] WINDOWSIZE rw — Size of sliding window used to monitor OCP interface activity for determination of auto-sleep feature. Time unit defined byCM_DYN_DEP_PRESCAL register.
  [22] GMAC_DYNDEP ro — Dynamic dependency towards GMAC clock domain
    1=ENABLED (Dependency is enabled)
  [12] L4CFG_DYNDEP ro — Dynamic dependency towards L4CFG clock domain
    1=ENABLED (Dependency is enabled)
  [7] L3INIT_DYNDEP ro — Dynamic dependency towards L3INIT clock domain
    1=ENABLED (Dependency is enabled)
  [6] CRC_DYNDEP ro — Dynamic dependency towards CRC clock domain
    1=ENABLED (Dependency is enabled)
  [3] IPU_DYNDEP ro — Dynamic dependency towards IPU clock domain
    1=ENABLED (Dependency is enabled)
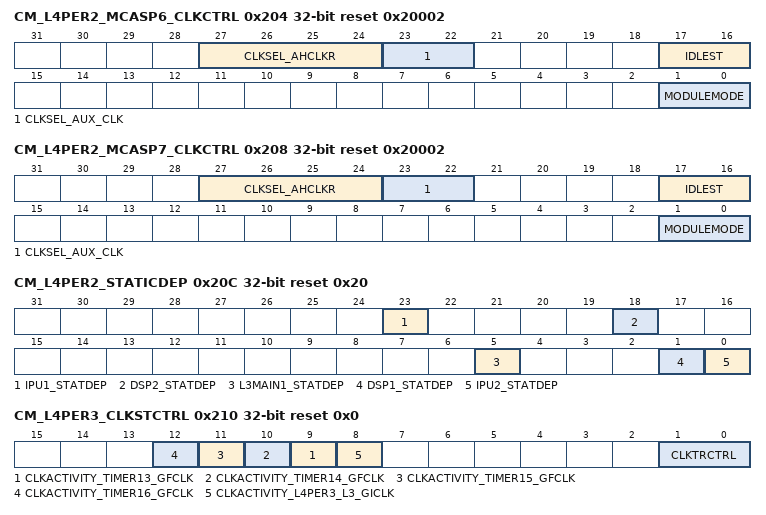
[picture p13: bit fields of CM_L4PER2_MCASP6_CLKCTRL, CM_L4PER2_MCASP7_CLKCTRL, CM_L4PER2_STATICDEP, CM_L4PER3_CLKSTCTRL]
0x204 CM_L4PER2_MCASP6_CLKCTRL reset 0x20002 — This register manages the MCASP2 clocks (SR2.0).
  [27:24] CLKSEL_AHCLKR rw — Selects reference clock for AHCLKR (SR2.0)
    values as CM_L4PER2_MCASP5_CLKCTRL.CLKSEL_AHCLKX
  [23:22] CLKSEL_AUX_CLK rw — Selects the source of the AUX clock.
    values as CM_L4PER2_MCASP5_CLKCTRL.CLKSEL_AUX_CLK
  [17:16] IDLEST ro — Module idle status. [warm reset insensitive]
    values as CM_L4PER2_L4_PER2_CLKCTRL.IDLEST
  [1:0] MODULEMODE ro — Control the way mandatory clocks are managed.
    values as CM_L4PER2_PRUSS1_CLKCTRL.MODULEMODE
0x208 CM_L4PER2_MCASP7_CLKCTRL reset 0x20002 — This register manages the MCASP3 clocks (SR2.0).
  fields as CM_L4PER2_MCASP6_CLKCTRL
0x20C CM_L4PER2_STATICDEP reset 0x20 — This register controls the static domain depedencies from L4PER2 domain towards 'target' domains. It is relevant only for domain having system initiator(s).
  [23] IPU1_STATDEP rw — Static dependency towards IPU1 clock domain
    values as CM_L4SEC_STATICDEP.L4PER_STATDEP
  [18] DSP2_STATDEP rw — Static dependency towards DSP2 clock domain
    values as CM_L4SEC_STATICDEP.L4PER_STATDEP
  [5] L3MAIN1_STATDEP ro — Static dependency towards L3MAIN1 clock domain
    1=ENABLED (Dependency is enabled)
  [1] DSP1_STATDEP rw — Static dependency towards DSP1 clock domain
    values as CM_L4SEC_STATICDEP.L4PER_STATDEP
  [0] IPU2_STATDEP rw — Static dependency towards IPU2 clock domain
    values as CM_L4SEC_STATICDEP.L4PER_STATDEP
0x210 CM_L4PER3_CLKSTCTRL reset 0x0 — This register enables the domain power state transition. It controls the HW supervised domain power state transition between ON-ACTIVE and ON-INACTIVE states. It also hold one status bit per clock input of the domain.
  [n-4] CLKACTIVITY_TIMER{n}_GFCLK ro (n=13..16) — This field indicates the state of the DMT{n}_GFCLK clock in the domain. [warm reset insensitive]
    values as CM_L4PER_CLKSTCTRL.CLKACTIVITY_L4PER_32K_GFCLK
  [8] CLKACTIVITY_L4PER3_L3_GICLK ro — This field indicates the state of the L4PER2_L3_GICLK clock in the domain. [warm reset insensitive]
    values as CM_L4PER_CLKSTCTRL.CLKACTIVITY_L4PER_32K_GFCLK
  [1:0] CLKTRCTRL rw — Controls the clock state transition of the L4PER clock domain.
    values as CM_L4PER_CLKSTCTRL.CLKTRCTRL
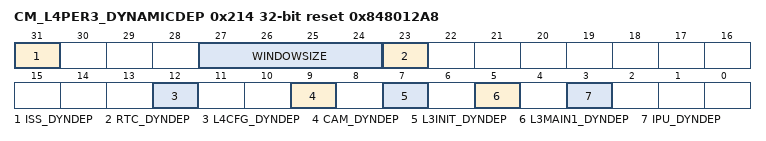
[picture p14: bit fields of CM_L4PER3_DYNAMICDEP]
0x214 CM_L4PER3_DYNAMICDEP reset 0x848012A8 — This register controls the dynamic domain depedencies from L4PER3 domain towards 'target' domains. It is relevant only for domain having OCP master port(s).
  [31] ISS_DYNDEP ro — Dynamic dependency towards ISS clock domain
    1=ENABLED (Dependency is enabled)
  [27:24] WINDOWSIZE rw — Size of sliding window used to monitor OCP interface activity for determination of auto-sleep feature. Time unit defined byCM_DYN_DEP_PRESCAL register.
  [23] RTC_DYNDEP ro — Dynamic dependency towards RTC clock domain
    1=ENABLED (Dependency is enabled)
  [12] L4CFG_DYNDEP ro — Dynamic dependency towards L4CFG clock domain
    1=ENABLED (Dependency is enabled)
  [9] CAM_DYNDEP ro — Dynamic dependency towards CAM clock domain
    1=ENABLED (Dependency is enabled)
  [7] L3INIT_DYNDEP ro — Dynamic dependency towards L3INIT clock domain
    1=ENABLED (Dependency is enabled)
  [5] L3MAIN1_DYNDEP ro — Dynamic dependency towards L3MAIN1 clock domain
    1=ENABLED (Dependency is enabled)
  [3] IPU_DYNDEP ro — Dynamic dependency towards IPU clock domain
    1=ENABLED (Dependency is enabled)
